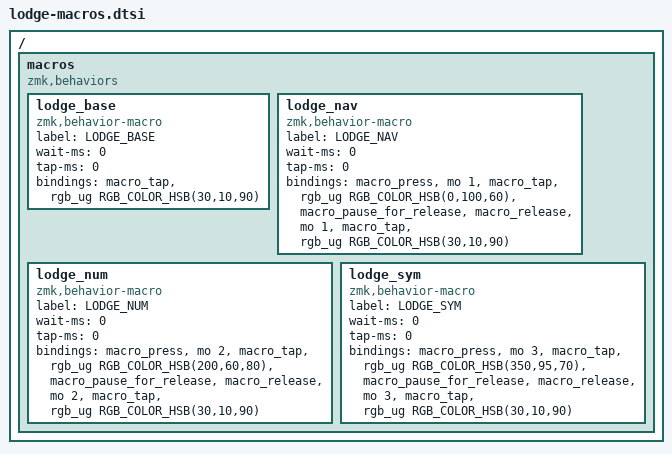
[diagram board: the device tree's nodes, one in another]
/ {
  macros {
    compatible = "zmk,behaviors";

    /* BASE color (warm white) */
    lodge_base: lodge_base {
      compatible = "zmk,behavior-macro";
      label = "LODGE_BASE";
      #binding-cells = <0>;
      wait-ms = <0>;
      tap-ms = <0>;
      bindings
        = <&macro_tap &rgb_ug RGB_COLOR_HSB(30,10,90)>;
    };

    /* NAV layer + BLACK LODGE red while held */
    lodge_nav: lodge_nav {
      compatible = "zmk,behavior-macro";
      label = "LODGE_NAV";
      #binding-cells = <0>;
      wait-ms = <0>;
      tap-ms = <0>;
      bindings
        = <&macro_press &mo 1>
        , <&macro_tap &rgb_ug RGB_COLOR_HSB(0,100,60)>
        , <&macro_pause_for_release>
        , <&macro_release &mo 1>
        , <&macro_tap &rgb_ug RGB_COLOR_HSB(30,10,90)>;
    };

    /* NUM layer + WHITE LODGE icy blue while held */
    lodge_num: lodge_num {
      compatible = "zmk,behavior-macro";
      label = "LODGE_NUM";
      #binding-cells = <0>;
      wait-ms = <0>;
      tap-ms = <0>;
      bindings
        = <&macro_press &mo 2>
        , <&macro_tap &rgb_ug RGB_COLOR_HSB(200,60,80)>
        , <&macro_pause_for_release>
        , <&macro_release &mo 2>
        , <&macro_tap &rgb_ug RGB_COLOR_HSB(30,10,90)>;
    };

    /* SYM layer + RED ROOM crimson while held */
    lodge_sym: lodge_sym {
      compatible = "zmk,behavior-macro";
      label = "LODGE_SYM";
      #binding-cells = <0>;
      wait-ms = <0>;
      tap-ms = <0>;
      bindings
        = <&macro_press &mo 3>
        , <&macro_tap &rgb_ug RGB_COLOR_HSB(350,95,70)>
        , <&macro_pause_for_release>
        , <&macro_release &mo 3>
        , <&macro_tap &rgb_ug RGB_COLOR_HSB(30,10,90)>;
    };
  };
};
